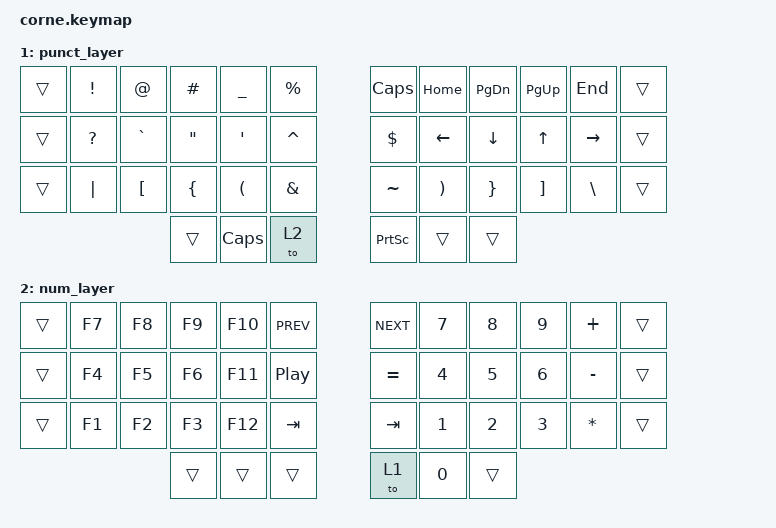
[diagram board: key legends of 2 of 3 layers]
/*
 * Copyright (c) 2020 The ZMK Contributors
 *
 * SPDX-License-Identifier: MIT
 */

#include <behaviors.dtsi>
#include <dt-bindings/zmk/keys.h>
#include <dt-bindings/zmk/bt.h>

#define DEFAULT 0
#define PUNCT   1
#define NUMS    2



/ {
        behaviors {
                hm: homerow_mods {
                        compatible = "zmk,behavior-hold-tap";
                        label = "HOMEROW_MODS";
                        #binding-cells = <2>;
                        tapping-term-ms = <200>;
                        quick_tap_ms = <0>;
                        flavor = "balanced";
                        bindings = <&kp>, <&kp>;
                };
                combos {
                  compatible = "zmk,combos";
                  combo_layer_escape {
                      timeout-ms = <50>;
                      key-positions = <37 40>;
                      bindings = <&to 0>;
                  };
                  combo_sticky_shift {
                      timeout-ms = <50>;
                      key-positions = <16 19>;
                      bindings = <&sk LSHIFT>;
                  };
                };
        };

        keymap {
                compatible = "zmk,keymap";

                default_layer {
// ┌───┬────────┬────────┬────────┬────────┬────────┐ ┌────────┬────────┬────────┬────────┬────────┬───┐
// | __|  Q     |  W     |  E     |  R     |  T     | |  Y     |  U     |  I     |  O     |  P     | __|
// ├───┼────────┼────────┼────────┼────────┼────────┤ ├────────┼────────┼────────┼────────┼────────┼───┤
// | __|  A/WIN |  S/ALT |  D/SFT |  F/CTRL|  G/NUMS| |  H/NUMS|  J/CTRL|  K/SFT |  L/ALT |  ;/WIN | __|
// ├───┼────────┼────────┼────────┼────────┼────────┤ ├────────┼────────┼────────┼────────┼────────┼───┤
// | __|  Z     |  X     |  C     |  V     |  B     | |  N     |  M     |  ,     |  .     |  /     | __|
// └───┴────────┴────────┼────────┼────────┼────────┤ ├────────┼────────┼────────┼────────┴────────┴───┘
//                       | ___    |NUMS/BSP| ENT    | | ESC    |PUNCT/SP| ___    |
//		                   └────────┴────────┴────────┘ └────────┴────────┴────────┘


                        bindings = <
   &trans  &kp Q       &kp W       &kp E         &kp R          &kp T         &kp Y       &kp U            &kp I          &kp O       &kp P          &trans
   &trans  &hm LCMD A  &hm LALT S  &hm LSHIFT D  &hm LCTRL F    &lt NUMS G    &lt NUMS H  &hm RCTRL J      &hm RSHIFT K   &hm RALT L  &hm RCMD SEMI  &trans
   &trans  &kp Z       &kp X       &kp C         &kp V          &kp B         &kp N       &kp M            &kp COMMA      &kp DOT     &kp FSLH       &trans
                                   &kp &trans    &lt NUMS BSPC  &kp RET       &kp ESC     &lt PUNCT SPACE  &trans
                        >;
                };

                punct_layer {
// ┌───┬────────┬────────┬────────┬────────┬────────┐ ┌────────┬────────┬────────┬────────┬────────┬───┐
// | __|  !     |  @     |  #     |  _     |  %     | |  CAPS  |  HOME  |  PGDN  |  PGUP  |  END   | __|
// ├───┼────────┼────────┼────────┼────────┼────────┤ ├────────┼────────┼────────┼────────┼────────┼───┤
// | __|  ?     |  `     |  "     |  '     |  ^     | |  $     |  LEFT  |  DOWN  |  UP    |  RIGHT | __|
// ├───┼────────┼────────┼────────┼────────┼────────┤ ├────────┼────────┼────────┼────────┼────────┼───┤
// | __|  |     |  [     |  {     |  (     |  &     | |  ~     |  )     |  }     |  ]     |  BSLSH | __|
// └───┴────────┴────────┼────────┼────────┼────────┤ ├────────┼────────┼────────┼────────┴────────┴───┘
//                       | ___    | CAPS   | NUMLK  | | PSCRN  | ___    | ___    |
//		                   └────────┴────────┴────────┘ └────────┴────────┴────────┘

                        bindings = <
   &trans  &kp EXCL   &kp AT     &kp HASH  &kp UNDER  &kp PRCNT        &kp CAPS  &kp HOME  &kp PG_DN &kp PG_UP &kp END    &trans
   &trans  &kp QMARK  &kp GRAVE  &kp DQT   &kp SQT    &kp CARET        &kp DLLR  &kp LEFT  &kp DOWN  &kp UP    &kp RIGHT  &trans
   &trans  &kp PIPE   &kp LBKT   &kp LBRC  &kp LPAR   &kp AMPS         &kp TILDE &kp RPAR  &kp RBRC  &kp RBKT  &kp BSLH   &trans
                                 &trans    &kp CAPS   &to 2            &kp PSCRN &trans    &trans
                        >;
                };

                num_layer {
// ┌───┬────────┬────────┬────────┬────────┬────────┐ ┌────────┬────────┬────────┬────────┬────────┬───┐
// | __|  F7    |  F8    |  F9    |  F10   |  PREV  | |  NEXT  |  7     |  8     |  9     |  +     | __|
// ├───┼────────┼────────┼────────┼────────┼────────┤ ├────────┼────────┼────────┼────────┼────────┼───┤
// | __|  F4    |  F5    |  F6    |  F11   |  PP    | |  =     |  4     |  5     |  6     |  -     | __|
// ├───┼────────┼────────┼────────┼────────┼────────┤ ├────────┼────────┼────────┼────────┼────────┼───┤
// | __|  F1    |  F2    |  F3    |  F12   |  TAB   | |  TAB   |  1     |  2     |  3     |  *     | __|
// └───┴────────┴────────┼────────┼────────┼────────┤ ├────────┼────────┼────────┼────────┴────────┴───┘
//                       | ___    | ___    |  ___   | | PUNCTLK|  0     | ___    |
//		                   └────────┴────────┴────────┘ └────────┴────────┴────────┘

                        bindings = <
   &trans  &kp F7  &kp F8  &kp F9  &kp F10  &kp C_PREV  &kp C_NEXT &kp N7  &kp N8  &kp N9  &kp PLUS    &trans
   &trans  &kp F4  &kp F5  &kp F6  &kp F11  &kp C_PP    &kp EQUAL  &kp N4  &kp N5  &kp N6  &kp MINUS   &trans
   &trans  &kp F1  &kp F2  &kp F3  &kp F12  &kp TAB     &kp TAB    &kp N1  &kp N2  &kp N3  &kp STAR    &trans
                           &trans  &trans   &trans      &to 1      &kp N0  &trans
                        >;
                };
               
        };
}; 
